# ZB204 register map
Vendor: GS; File version: 1.2
CPU: CM3 r2p0, little endian, MPU, no FPU, VTOR, 3 interrupt priority bits
Registers are 32-bit, read-write, reset 0x0 unless marked. A register's access mark holds for its fields unless they carry their own. Offsets are from the block's base; [hi:lo] are bit positions; {n}, {i} and the like mark numbered series.

## SWT — Software Watchdog Timer
Base 0x401E0000
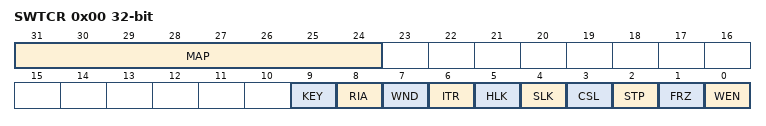
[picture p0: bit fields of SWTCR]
0x00 SWTCR — SWT Control Register
  [31:24] MAP — Wait Mode Bit
  [9] KEY — Wait Mode Bit
    0=Fixed Service; 1=Keyed Service
  [8] RIA — Doze Mode Bit
    0=generates a bus error; 1=causes a system reset if WEN=1
  [7] WND — STOP Mode Bit
    0=Regular mode; 1=Windowed mode
  [6] ITR — Debug Mode Bit
    0=reset; 1=interrupt
  [5] HLK — Watchdog Clock Domain Interrupt Status Bit
    0=read/write; 1=read-only
  [4] SLK — Watchdog Timer Prescaler
    0=read/write; 1=read-only
  [3] CSL — Watchdog Interrupt Flag Bit
    0=System; 1=Oscillator
  [2] STP — Watchdog Change Update Bit
    0=continues to run; 1=stopped
  [1] FRZ — Watchdog Change Update Bit
    0=continues to run; 1=stopped
  [0] WEN — Watchdog Enable Bit
    0=disabled; 1=enabled
0x04 SWTIR — SWT Interrupt Register
  [0] TIF — Timeout Interrupt Flag
    0=No interrupt; 1=Interrupt request
0x08 SWTTO — SWT Timeout Register
0x0C SWTWN — SWT Window Register
0x10 SWTSR — SWT Service Register
  [15:0] WSC — Watchdog Service Code
0x14 SWTCO — SWT Counter Output Register
0x18 SWTSK — SWT Service Key Register
  [15:0] SK — Service Key

## AES
Base 0x40600000
0x00 DIOR
{0x10+4i} KEY[{i}] (i=0..7) — KEY[{i}]
0x30 CSR
{0x34+4i} COUNTER[{i}] (i=0..3) — COUNTER[{i}]

## CRC
Base 0x40400000
0x00 CTR
0x04 RES
0x08 INI
0x0C DATI

## ADC — Analog-to-digital converter
Base 0x40060000
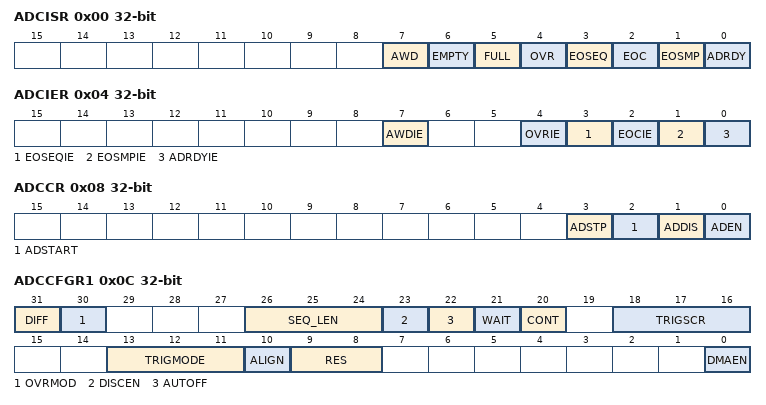
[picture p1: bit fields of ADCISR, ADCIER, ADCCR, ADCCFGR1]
0x00 ADCISR — ADC interrupt and status register
  [7] AWD — Analog watchdog flag
    0=No event; 1=event
  [6] EMPTY — FIFO empty status
    0=not empty; 1=empty
  [5] FULL — FIFO full status
    0=not full; 1=full
  [4] OVR — ADC overrun
    0=No; 1=Overrun
  [3] EOSEQ — End of sequence flag
    0=not complete; 1=complete
  [2] EOC — End of conversion flag
    0=not complete; 1=complete
  [1] EOSMP — End of sampling flag
    0=Not end; 1=End
  [0] ADRDY — ADC ready
    0=not yet ready; 1=ready
0x04 ADCIER — ADC interrupt enable register
  [all] fields
    0=disabled; 1=enabled
  [7] AWDIE — Analog watchdog interrupt enable
  [4] OVRIE — Overrun interrupt enable
  [3] EOSEQIE — End of conversion sequence interrupt enable
  [2] EOCIE — End of conversion interrupt enable
  [1] EOSMPIE — End of sampling flag interrupt enable
  [0] ADRDYIE — ADC ready interrupt enable
0x08 ADCCR — ADC control register
  [3] ADSTP — ADC stop conversion command
  [2] ADSTART — ADC start conversion command
  [1] ADDIS — ADC disable command
  [0] ADEN — ADC enable command
0x0C ADCCFGR1 — ADC configuration register 1
  [31] DIFF — Select differential-input
    0=single; 1=differentially
  [30] OVRMOD — Overrun management mode
    0=old data; 1=overwritten
  [26:24] SEQ_LEN — Sequence length
  [23] DISCEN — Discontinuous mode
    0=disabled; 1=enabled
  [22] AUTOFF — Auto-off mode
    0=disabled; 1=enabled
  [21] WAIT — Wait conversion mode
    0=disabled; 1=enabled
  [20] CONT — Single / continuous conversion mode
    0=Single; 1=continuous
  [18:16] TRIGSCR — External trigger source
  [13:11] TRIGMODE — Trigger mode select
  [10] ALIGN — Data alignment
    0=Left; 1=Right
  [9:8] RES — Data resolution
  [0] DMAEN — Direct memory access enable
    0=disabled; 1=enabled
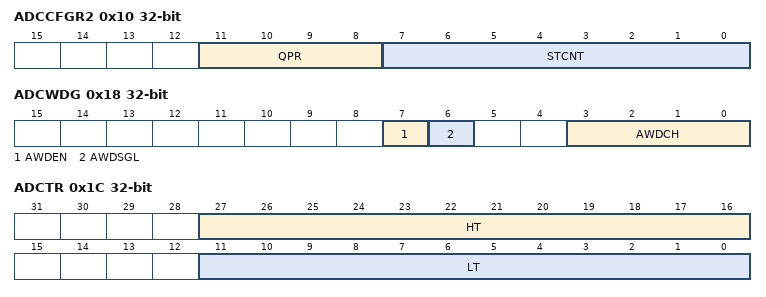
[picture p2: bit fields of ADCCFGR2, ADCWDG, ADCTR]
0x10 ADCCFGR2 — ADC configuration register 2
  [11:8] QPR — Prescaler Clock Divider Bits
  [7:0] STCNT — ADC startup counter bits
0x14 ADCSMPR — ADC sampling time register
  [7:0] SMP — Sampling time selection
0x18 ADCWDG — ADC watch dog register
  [7] AWDEN — End of conversion flag
    0=disabled; 1=enabled
  [6] AWDSGL — Enable the watchdog on a single channel or on all channels
    0=all channels; 1=single channel
  [3:0] AWDCH — Analog watchdog channel selection
0x1C ADCTR — ADC watchdog threshold register
  [27:16] HT — Analog watchdog higher threshold
  [11:0] LT — Analog watchdog lower threshold
{0x2C+i} ADCCHSELR_CCW[{i}] (i=0..7) 8-bit — ADC channel selection register
  [3:0] CCW — ADC ready
0x4C ADCFIFO — ADC FIFO access register
  [15:0] DATA — Converted data
